# STM32MP157 register map
File version: 1.7
CPU: CM4 r0p1, little endian, no MPU, FPU, 4 interrupt priority bits
Registers are 32-bit, read-write, reset 0x0 unless marked. A register's access mark holds for its fields unless they carry their own. Offsets are from the block's base; [hi:lo] are bit positions; {n}, {i} and the like mark numbered series; 'fields as' and 'values as' point back to an identical list.

## NVIC — Nested Vectored Interrupt Controller
Base 0xE000E100
{0x0+4i} ISER{i} (i=0..3) — Interrupt Set-Enable Register
  [31:0] SETENA
0x10 ISER4 — Interrupt Set-Enable Register
{0x80+4i} ICER{i} (i=0..3) — Interrupt Clear-Enable Register
  [31:0] CLRENA
0x90 ICER4 — Interrupt Clear-Enable Register
{0x100+4i} ISPR{i} (i=0..3) — Interrupt Set-Pending Register
  [31:0] SETPEND
0x110 ISPR4 — Interrupt Set-Pending Register
{0x180+4i} ICPR{i} (i=0..3) — Interrupt Clear-Pending Register
  [31:0] CLRPEND
0x1C4 ICPR4 — Interrupt Clear-Pending Register
{0x200+4i} IABR{i} ro (i=0..3) — Interrupt Active Bit Register
  [31:0] ACTIVE
0x210 IABR4 — Interrupt Active Bit Register
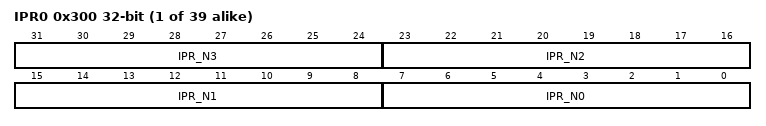
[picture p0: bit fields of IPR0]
{0x300+4i} IPR{i} (i=0..38) — Interrupt Priority Register
  [8n+7:8n] IPR_N{n} (n=0..3)

## QUADSPI — QUADSPI1
Base 0x58003000
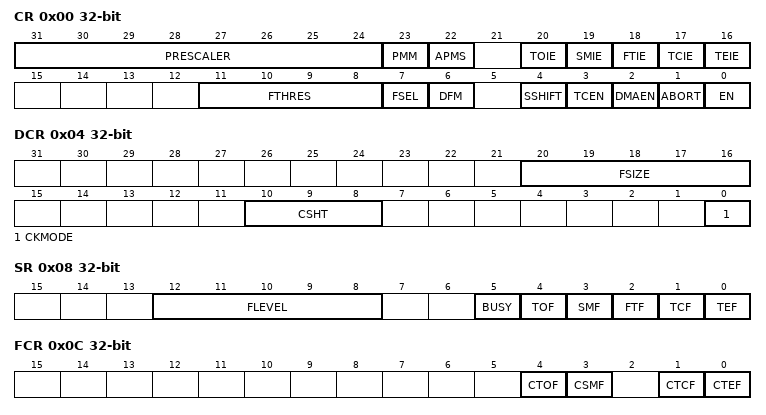
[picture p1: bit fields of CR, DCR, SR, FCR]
0x00 CR — QUADSPI control register
  [31:24] PRESCALER, [23] PMM, [22] APMS, [20] TOIE, [19] SMIE, [18] FTIE, [17] TCIE, [16] TEIE, [11:8] FTHRES, [7] FSEL, [6] DFM, [4] SSHIFT, [3] TCEN, [2] DMAEN, [1] ABORT, [0] EN
0x04 DCR — QUADSPI device configuration register
  [20:16] FSIZE, [10:8] CSHT, [0] CKMODE
0x08 SR ro — QUADSPI status register
  [12:8] FLEVEL, [5] BUSY, [4] TOF, [3] SMF, [2] FTF, [1] TCF, [0] TEF
0x0C FCR wo — QUADSPI flag clear register
  [4] CTOF, [3] CSMF, [1] CTCF, [0] CTEF
0x10 DLR — QUADSPI data length register
  [31:0] DL
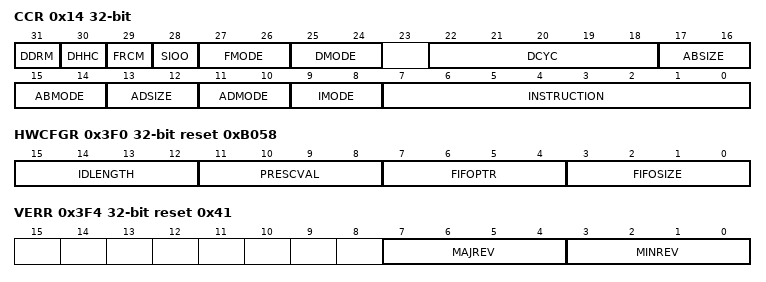
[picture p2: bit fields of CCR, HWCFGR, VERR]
0x14 CCR — QUADSPI communication configuration register
  [31] DDRM, [30] DHHC, [29] FRCM, [28] SIOO, [27:26] FMODE, [25:24] DMODE, [22:18] DCYC, [17:16] ABSIZE, [15:14] ABMODE, [13:12] ADSIZE, [11:10] ADMODE, [9:8] IMODE, [7:0] INSTRUCTION
0x18 AR — QUADSPI address register
  [31:0] ADDRESS
0x1C ABR — QUADSPI alternate bytes registers
  [31:0] ALTERNATE
0x20 DR — QUADSPI data register
  [31:0] DATA
0x24 PSMKR — QUADSPI polling status mask register
  [31:0] MASK
0x28 PSMAR — QUADSPI polling status match register
  [31:0] MATCH
0x2C PIR — QUADSPI polling interval register
  [15:0] INTERVAL
0x30 LPTR — QUADSPI low-power timeout register
  [15:0] TIMEOUT
0x3F0 HWCFGR ro reset 0xB058 — QUADSPI HW configuration register
  [15:12] IDLENGTH, [11:8] PRESCVAL, [7:4] FIFOPTR, [3:0] FIFOSIZE
0x3F4 VERR ro reset 0x41 — QUADSPI version register
  [7:4] MAJREV, [3:0] MINREV
0x3F8 IPIDR ro reset 0x140031 — QUADSPI identification register
  [31:0] ID
0x3FC SIDR ro reset 0xA3C5DD01 — QUADSPI size identification register
  [31:0] SID

## RNG1
Base 0x54003000
Same registers: RNG2 0x4C003000
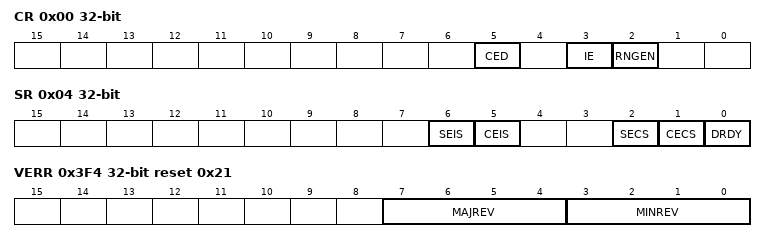
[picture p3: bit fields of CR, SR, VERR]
0x00 CR — RNG control register
  [5] CED, [3] IE, [2] RNGEN
0x04 SR access per field — RNG status register
  [6] SEIS rw, [5] CEIS rw, [2] SECS ro, [1] CECS ro, [0] DRDY ro
0x08 DR ro — The RNG_DR register is a read-only register.
  [31:0] RNDATA
0x3F0 HWCFGR ro reset 0x6 — RNG hardware configuration register
0x3F4 VERR ro reset 0x21 — RNG version register
  [7:4] MAJREV, [3:0] MINREV
0x3F8 IPIDR ro reset 0x170041 — RNG identification register
  [31:0] ID
0x3FC SIDR ro reset 0xA3C5DD01 — RNG size ID register
  [31:0] SID

## SAI1 — SAI1 register block
Base 0x4400A000
Same registers: SAI2 0x4400B000, SAI3 0x4400C000, SAI4 0x50027000
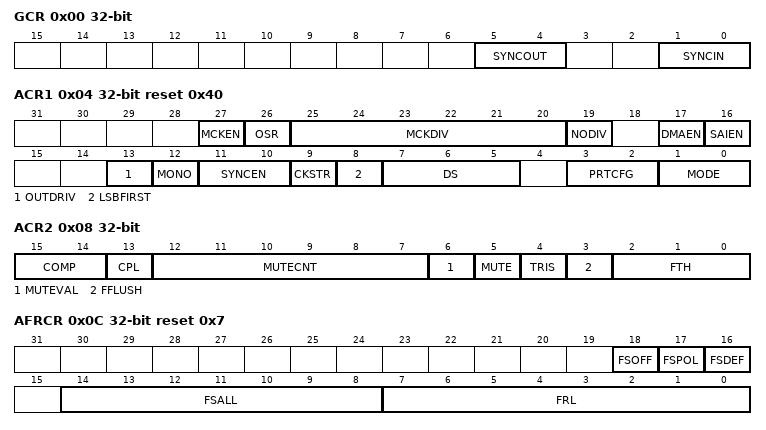
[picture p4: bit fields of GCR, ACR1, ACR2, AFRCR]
0x00 GCR — Global configuration register
  [5:4] SYNCOUT, [1:0] SYNCIN
0x04 ACR1 reset 0x40 — Configuration register 1
  [27] MCKEN, [26] OSR, [25:20] MCKDIV, [19] NODIV, [17] DMAEN, [16] SAIEN, [13] OUTDRIV, [12] MONO, [11:10] SYNCEN, [9] CKSTR, [8] LSBFIRST, [7:5] DS, [3:2] PRTCFG, [1:0] MODE
0x08 ACR2 access per field — Configuration register 2
  [15:14] COMP rw, [13] CPL rw, [12:7] MUTECNT rw, [6] MUTEVAL rw, [5] MUTE rw, [4] TRIS rw, [3] FFLUSH wo, [2:0] FTH rw
0x0C AFRCR reset 0x7 — This register has no meaning in and SPDIF audio protocol
  [18] FSOFF, [17] FSPOL, [16] FSDEF, [14:8] FSALL, [7:0] FRL
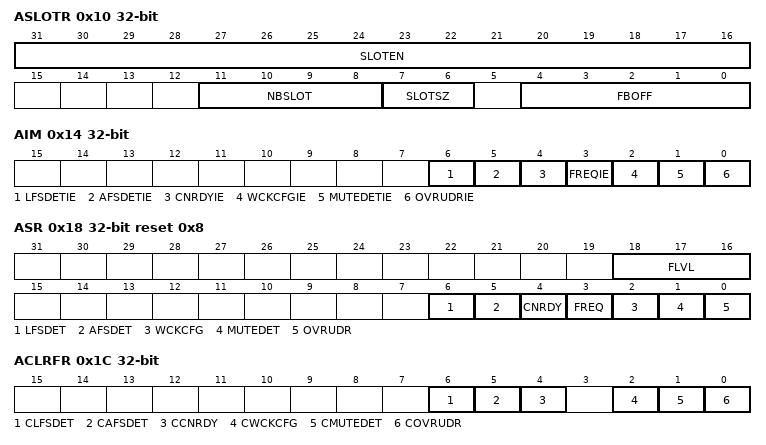
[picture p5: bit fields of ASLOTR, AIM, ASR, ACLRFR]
0x10 ASLOTR — This register has no meaning in and SPDIF audio protocol
  [31:16] SLOTEN, [11:8] NBSLOT, [7:6] SLOTSZ, [4:0] FBOFF
0x14 AIM — Interrupt mask register
  [6] LFSDETIE, [5] AFSDETIE, [4] CNRDYIE, [3] FREQIE, [2] WCKCFGIE, [1] MUTEDETIE, [0] OVRUDRIE
0x18 ASR ro reset 0x8 — Status register
  [18:16] FLVL, [6] LFSDET, [5] AFSDET, [4] CNRDY, [3] FREQ, [2] WCKCFG, [1] MUTEDET, [0] OVRUDR
0x1C ACLRFR wo — Clear flag register
  [6] CLFSDET, [5] CAFSDET, [4] CCNRDY, [2] CWCKCFG, [1] CMUTEDET, [0] COVRUDR
0x20 ADR — Data register
  [31:0] DATA
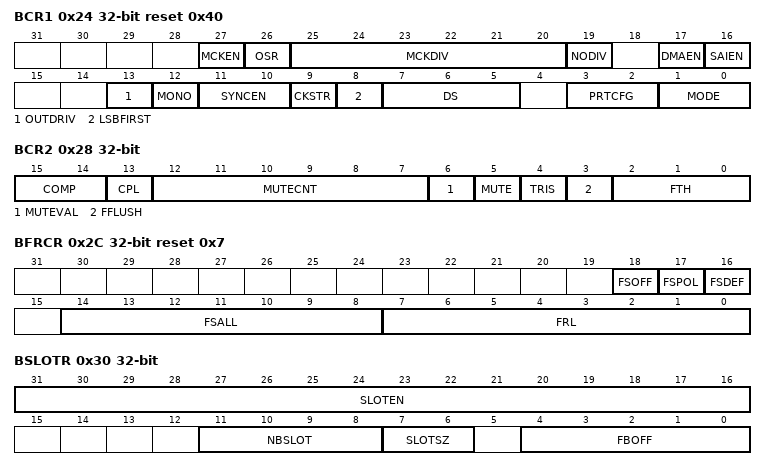
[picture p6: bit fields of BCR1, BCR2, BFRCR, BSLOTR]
0x24 BCR1 reset 0x40 — Configuration register 1
  fields as ACR1
0x28 BCR2 access per field — Configuration register 2
  fields as ACR2
0x2C BFRCR reset 0x7 — This register has no meaning in and SPDIF audio protocol
  [18] FSOFF, [17] FSPOL, [16] FSDEF, [14:8] FSALL, [7:0] FRL
0x30 BSLOTR — This register has no meaning in and SPDIF audio protocol
  [31:16] SLOTEN, [11:8] NBSLOT, [7:6] SLOTSZ, [4:0] FBOFF
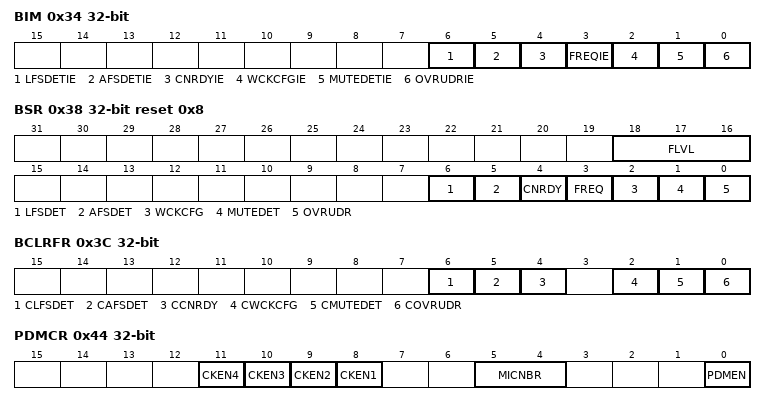
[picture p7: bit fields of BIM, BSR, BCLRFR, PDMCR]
0x34 BIM — Interrupt mask register
  fields as AIM
0x38 BSR ro reset 0x8 — Status register
  fields as ASR
0x3C BCLRFR wo — Clear flag register
  fields as ACLRFR
0x40 BDR — Data register
  [31:0] DATA
0x44 PDMCR — PDM control register
  [n+7] CKEN{n} (n=1..4), [5:4] MICNBR, [0] PDMEN
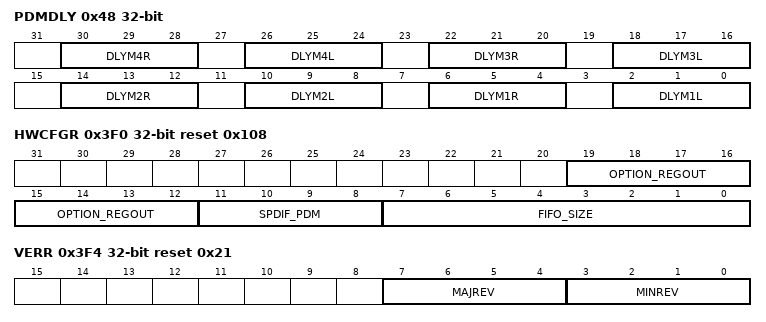
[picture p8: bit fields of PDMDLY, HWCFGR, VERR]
0x48 PDMDLY — PDM delay register
  [8n-2:8n-4] DLYM{n}R (n=1..4), [8n-6:8n-8] DLYM{n}L (n=1..4)
0x3F0 HWCFGR ro reset 0x108 — SAI hardware configuration register
  [19:12] OPTION_REGOUT, [11:8] SPDIF_PDM, [7:0] FIFO_SIZE
0x3F4 VERR ro reset 0x21 — SAI version register
  [7:4] MAJREV, [3:0] MINREV
0x3F8 IPIDR ro reset 0x130031 — SAI identification register
  [31:0] ID
0x3FC SIDR ro reset 0xA3C5DD01 — SAI size identification register
  [31:0] SID
